# FM33A0XXEV register map
File version: 1.0
CPU: SC000, little endian, no MPU, no FPU, 3 interrupt priority bits
Registers are 32-bit, read-write, reset 0x0 unless marked. A register's access mark holds for its fields unless they carry their own. Offsets are from the block's base; [hi:lo] are bit positions; {n}, {i} and the like mark numbered series.

## RTC — RTC module information
Base 0x40011000
0x00 WER — RTC Write Enable Register
  [0] RTCWE — RTCWE field description
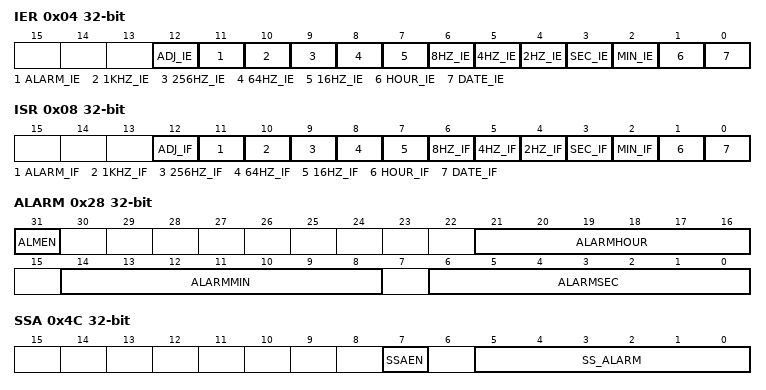
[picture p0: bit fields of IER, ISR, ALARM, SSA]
0x04 IER — RTC Interrupt Enable Register
  [12] ADJ_IE — ADJ_IE field description
  [11] ALARM_IE — ALARM_IE field description
  [10] 1KHZ_IE — 1KHZ_IE field description
  [9] 256HZ_IE — 256HZ_IE field description
  [8] 64HZ_IE — 64HZ_IE field description
  [7] 16HZ_IE — 16HZ_IE field description
  [6] 8HZ_IE — 8HZ_IE field description
  [5] 4HZ_IE — 4HZ_IE field description
  [4] 2HZ_IE — 2HZ_IE field description
  [3] SEC_IE — SEC_IE field description
  [2] MIN_IE — MIN_IE field description
  [1] HOUR_IE — HOUR_IE field description
  [0] DATE_IE — DATE_IE field description
0x08 ISR — RTC Interrupt Status Register
  [12] ADJ_IF — ADJ_IF field description
  [11] ALARM_IF — ALARM_IF field description
  [10] 1KHZ_IF — 1KHZ_IF field description
  [9] 256HZ_IF — 256HZ_IF field description
  [8] 64HZ_IF — 64HZ_IF field description
  [7] 16HZ_IF — 16HZ_IF field description
  [6] 8HZ_IF — 8HZ_IF field description
  [5] 4HZ_IF — 4HZ_IF field description
  [4] 2HZ_IF — 2HZ_IF field description
  [3] SEC_IF — SEC_IF field description
  [2] MIN_IF — MIN_IF field description
  [1] HOUR_IF — HOUR_IF field description
  [0] DATE_IF — DATE_IF field description
0x0C BCDSEC — RTC BCD Second register
  [6:0] BCDSEC — BCDSEC field description
0x10 BCDMIN — RTC BCD Minute register
  [6:0] BCDMIN — BCDMIN field description
0x14 BCDHOUR — RTC BCD Hour register
  [5:0] BCDHOUR — BCDHOUR field description
0x18 BCDDATE — RTC BCD Date register
  [5:0] BCDDATE — BCDDATE field description
0x1C BCDWEEK — RTC BCD Week register
  [2:0] BCDWEEK — BCDWEEK field description
0x20 BCDMONTH — RTC BCD Month register
  [4:0] BCDMONTH — BCDMONTH field description
0x24 BCDYEAR — RTC BCD Year register
  [7:0] BCDYEAR — BCDYEAR field description
0x28 ALARM — RTC Alarm Register
  [31] ALMEN — ALMEN field description
  [21:16] ALARMHOUR — ALARMHOUR field description
  [14:8] ALARMMIN — ALARMMIN field description
  [6:0] ALARMSEC — ALARMSEC field description
0x2C TMSEL — RTC Time Mark Select
  [3:0] FSEL — FSEL field description
0x30 ADJUST — RTC time Adjust Register
  [12:0] ADJUST — ADJUST field description
0x34 ADSIGN — RTC time Adjust Sign Register
  [0] ADSIGN — ADSIGN field description
0x38 VCAL — RTC virtual Calibration Register
  [0] PR1SEN — PR1SEN field description
0x3C MSCNT — RTC Milli-Second Register
  [7:0] MSCNT — MSCNT field description
0x40 CALSTEP — RTC Calibration Step Register
  [1:0] CALSTEP — CALSTEP field description
0x44 ADCNT — RTC Adjust Counter Register
  [8:0] ADJCNT ro — ADJCNT field description
0x48 SSR — RTC Sub-Second Register
  [5:0] SSR ro — SSR field description
0x4C SSA — RTC Sub-Second Alarm Register
  [7] SSAEN — SSAEN field description
  [5:0] SS_ALARM — SS_ALARM field description
0x50 DTR — RTC Time Mark Duty Cycle Register
  [24:0] DUTY — DUTY field description
0x7C CR — RTC Control Register
  [0] RTC_EN — RTC_EN field description

## LCD — LCD module information
Base 0x40010C00
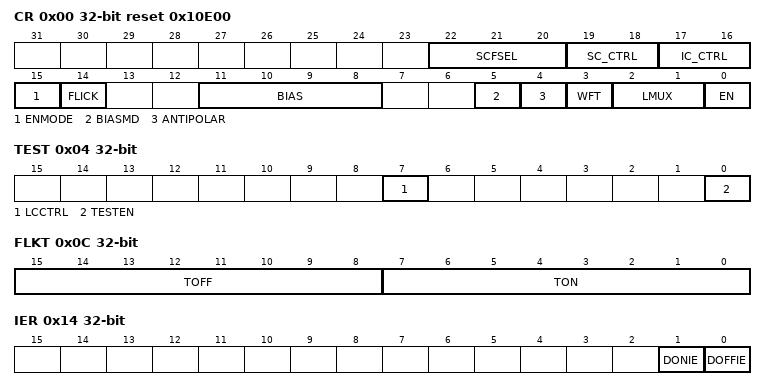
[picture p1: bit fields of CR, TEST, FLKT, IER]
0x00 CR reset 0x10E00 — LCD Control Register
  [22:20] SCFSEL — SCFSEL field description
  [19:18] SC_CTRL — SC_CTRL field description
  [17:16] IC_CTRL — IC_CTRL field description
  [15] ENMODE — ENMODE field description
  [14] FLICK — FLICK field description
  [11:8] BIAS — BIAS field description
  [5] BIASMD — BIASMD field description
  [4] ANTIPOLAR — ANTIPOLAR field description
  [3] WFT — WFT field description
  [2:1] LMUX — LMUX field description
  [0] EN — EN field description
0x04 TEST — LCD test Register
  [7] LCCTRL — LCCTRL field description
  [0] TESTEN — TESTEN field description
0x08 FCR — LCD Frequency Control Register
  [7:0] DF — DF field description
0x0C FLKT — LCD Flick Time Register
  [15:8] TOFF — TOFF field description
  [7:0] TON — TON field description
0x14 IER — LCD Interrupt Enable Register
  [1] DONIE — DONIE field description
  [0] DOFFIE — DOFFIE field description
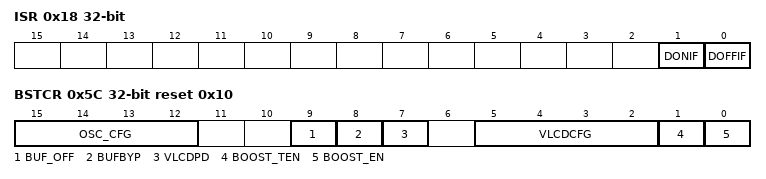
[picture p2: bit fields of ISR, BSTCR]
0x18 ISR — LCD Interrupt Status Register
  [1] DONIF — DONIF field description
  [0] DOFFIF — DOFFIF field description
{0x24+4i} DATA{i} (i=0..7) — LCD data buffer registers {i}
  [31:0] DSDA — DSDA field description
0x50 COMEN — LCD COM Enable Register
  [3:0] COMEN — COMEN field description
0x54 SEGEN0 — LCD SEG Enable Register0
  [31:0] SEGENx — SEGENx field description
0x58 SEGEN1 — LCD SEG Enable Register1
  [11:0] SEGENx — SEGENx field description
0x5C BSTCR reset 0x10 — LCD Boost Control Register
  [15:12] OSC_CFG — OSC_CFG field description
  [9] BUF_OFF — BUF_OFF field description
  [8] BUFBYP — BUFBYP field description
  [7] VLCDPD — VLCDPD field description
  [5:2] VLCDCFG — VLCDCFG field description
  [1] BOOST_TEN — BOOST_TEN field description
  [0] BOOST_EN — BOOST_EN field description
